# DSI_PHY register map
Vendor: Texas Instruments
Peripheral module from a debugger description file (folder omap36xx).
Registers are 32-bit, read-write, reset 0x625D21A0 unless marked. A register's access mark holds for its fields unless they carry their own. Offsets are as the file gives them; lines under a group give offsets from that group; [hi:lo] are bit positions; {n}, {i} and the like mark numbered series; 'fields as' and 'values as' point back to an identical list; <NAME> marks a mode.

## DSI_PHY
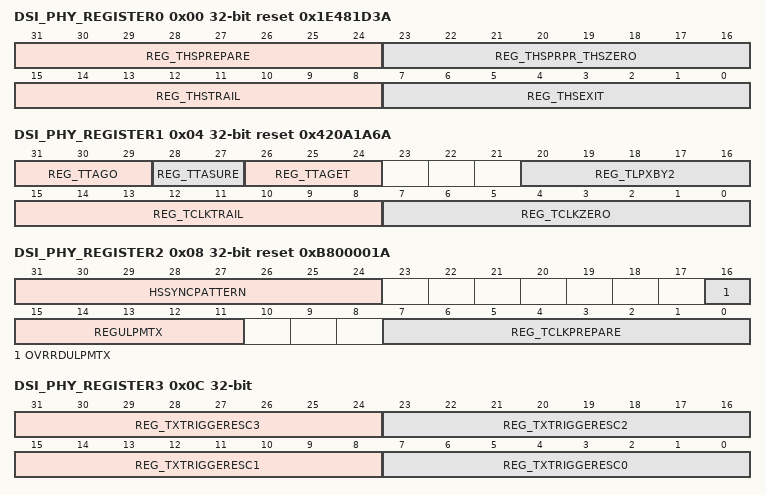
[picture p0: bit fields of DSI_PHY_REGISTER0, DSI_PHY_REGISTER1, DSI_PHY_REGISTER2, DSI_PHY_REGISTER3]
0x00 DSI_PHY_REGISTER0 reset 0x1E481D3A — Configuration register for HS mode timings
  [31:24] REG_THSPREPARE — REG_THSPREPARE timing parameter in multiples of DDR clock period. DDR clock = CLKIN4DDR/4.D-PHY specification: 40 ns + 4*UI ÷ 85 ns + 6*UI. . UI = Unit Interval, equal to the duration of any HS state on the clock lane . Default value is programmed for 400 MHz. .
  [23:16] REG_THSPRPR_THSZERO — REG_THSPRPR_THSZERO timing parameter in multiples of DDR clock period. DDR clock = CLKIN4DDR/4.D-PHY specification: 145 ns + 10*UI . Default value is programmed for 400 MHz. .
  [15:8] REG_THSTRAIL — REG_THSTRAIL timing parameter in multiples of DDR clock period. DDR clock = CLKIN4DDR/4.D-PHY specification: 60 ns + 4*UI . Default value is programmed for 400 MHz. .
  [7:0] REG_THSEXIT — REG_THSEXIT timing parameter in multiples of DDR clock period. DDR clock = CLKIN4DDR/4)D-PHY specification: 100 ns . Default value is programmed for 400 MHz. .
0x04 DSI_PHY_REGISTER1 access per field reset 0x420A1A6A — Configuration register for LP mode and HS mode timings
  [31:29] REG_TTAGO rw — TTA-GO timing in terms of number of TXCLKESC clocksDefault value: 4 cycles .
    {v}={v+2} cycles (v=0..7)
  [28:27] REG_TTASURE rw — TTA-SURE timing in terms of number of TXCLKESC clocksDefault value: 2 cycles .
    0=2 cycles; 1=1 cycle; 2=3 cycles; 3=4 cycles
  [26:24] REG_TTAGET rw — TTA-GET timing in terms of number of TXCLKESC clocksDefault value: 5 cycles .
    {v}={v+3} cycles (v=0..7)
  [20:16] REG_TLPXBY2 rw — (TLPX)/2 timing parameter in multiples of DDR clock frequency. DDR clock = CLKIN4DDR/4.Default value is programmed for 400 MHz . This is the internal timer value. The value seen on line will have variance due to rise/fall mismatch effects. . Note:TLPX is used to define the length of LP-01 state in HS Start of Transmission sequences on clock and data lanes. For all other purposes TLPX is defined by the period of TxLPEsc clock. .
  [15:8] REG_TCLKTRAIL rw — REG_TCLKTRAIL timing parameter in multiples of DDR clock frequency. DDR clock = CLKIN4DDR/4.D-PHY specification: 60 ns . Default value is programmed for 400 MHz. .
  [7:0] REG_TCLKZERO rw — REG_TCLKZERO timing parameter in multiples of DDR clock period. DDR clock = CLKIN4DDR/4.D-PHY specification: (REG_TCLKPREPARE + REG_TCLKZERO) 300 ns . Derived specification for REG_TCLKZERO (Min REG_TCLKPREPARE = 38 ns): REG_TCLKZERO 262 ns . Default value is programmed for 400 MHz. .
0x08 DSI_PHY_REGISTER2 access per field reset 0xB800001A — Sync pattern and reserved bits
  [31:24] HSSYNCPATTERN rw — Default : 184 (10111000). MSB (last received bit of sync pattern), LSB (first received bit of sync pattern).
  [16] OVRRDULPMTX rw — Global enable of the weak pulldown on the DSI lanes, configured through the REGULPMTX [15:11] bit field:
    1=Enable weak pulldown on the DSI lanes; 0=Disable weak pulldown on the DSI lanes (default)
  [15:11] REGULPMTX rw — Configuration of the weak pulldowns on the DSI lanes.For each bit, the following settings are applicable: . Bit [15]: Reserved . Bit [14]: Reserved . Bit [13]: DSI lane 2 . Bit [12]: DSI lane 1 . Bit [11]: DSI lane 0 .
    1=Enable weak pulldown on the lane; 0=Disable weak pulldown on the lane (default)
  [7:0] REG_TCLKPREPARE rw — REG_TCLKPREPARE timing parameter in multiples of DDR clock period. DDR clock = CLKIN4DDR/4.D-PHY specification: 38 ns ÷ 95 ns . Default value is programmed for 400 MHz. .
0x0C DSI_PHY_REGISTER3 — Transmitted pattern in case of escape mode trigger command transmission
  [31:24] REG_TXTRIGGERESC3 — Transmitted pattern when REG_TXTRIGGERESC3 is asserted (first bit transmitted to last bit transmitted)Default: 01100010 .
  [23:16] REG_TXTRIGGERESC2 — Default: 01011101
  [15:8] REG_TXTRIGGERESC1 — Default: 00100001
  [7:0] REG_TXTRIGGERESC0 — Default: 10100000
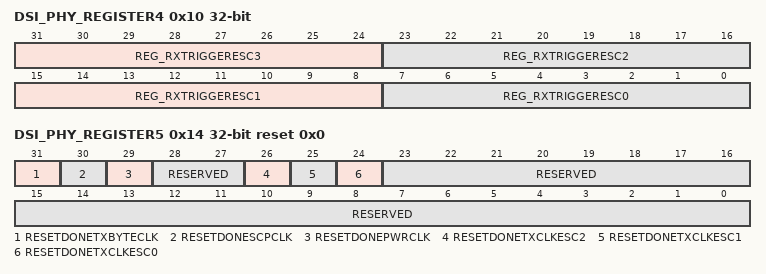
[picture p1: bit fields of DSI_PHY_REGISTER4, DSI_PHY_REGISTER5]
0x10 DSI_PHY_REGISTER4 — Received pattern for low-power trigger reception
  [31:24] REG_RXTRIGGERESC3 — Received pattern when REG_RXTRIGGERESC3 is asserted (first bit transmitted to last bit transmitted)Default: 01100010 .
  [23:16] REG_RXTRIGGERESC2 — Default: 01011101
  [15:8] REG_RXTRIGGERESC1 — Default: 00100001
  [7:0] REG_RXTRIGGERESC0 — Default: 10100000
0x14 DSI_PHY_REGISTER5 ro reset 0x0 — Reset done bits
  [31] RESETDONETXBYTECLK
    0=No reset; 1=Reset done for the TXBYTECLK domain
  [30] RESETDONESCPCLK
    0=No reset; 1=Reset done for the SCP clock domain
  [29] RESETDONEPWRCLK
    0=No reset; 1=Reset done for the PWR clock domain
  [28:27] RESERVED — Read-only register. Read returns 0.
  [26] RESETDONETXCLKESC2
    0=No reset; 1=Reset done for the TXCLKESC domain for lane 2
  [25] RESETDONETXCLKESC1
    0=No reset; 1=Reset done for the TXCLKESC domain for lane 1
  [24] RESETDONETXCLKESC0
    0=No reset; 1=Reset done for the TXCLKESC domain for lane 0
  [23:0] RESERVED — Read-only register. Read returns 0.
